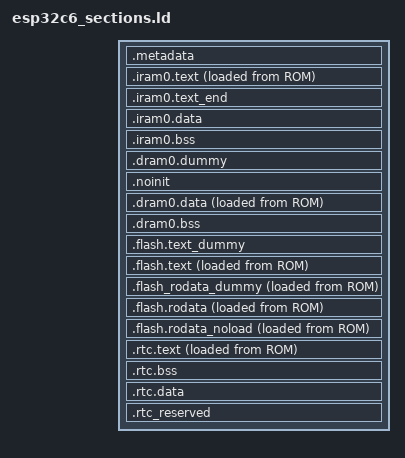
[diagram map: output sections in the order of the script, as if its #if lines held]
/****************************************************************************
 * boards/risc-v/esp32c6/common/scripts/esp32c6_sections.ld
 *
 * SPDX-License-Identifier: Apache-2.0
 *
 * Licensed to the Apache Software Foundation (ASF) under one or more
 * contributor license agreements.  See the NOTICE file distributed with
 * this work for additional information regarding copyright ownership.  The
 * ASF licenses this file to you under the Apache License, Version 2.0 (the
 * "License"); you may not use this file except in compliance with the
 * License.  You may obtain a copy of the License at
 *
 *   http://www.apache.org/licenses/LICENSE-2.0
 *
 * Unless required by applicable law or agreed to in writing, software
 * distributed under the License is distributed on an "AS IS" BASIS, WITHOUT
 * WARRANTIES OR CONDITIONS OF ANY KIND, either express or implied.  See the
 * License for the specific language governing permissions and limitations
 * under the License.
 *
 ****************************************************************************/

#include "common.ld"

/* Default entry point: */

ENTRY(__start);

SECTIONS
{
#ifdef CONFIG_ESPRESSIF_BOOTLOADER_MCUBOOT
  .metadata :
  {
    /* Magic for load header */

    LONG(0xace637d3)

    /* Application entry point address */

    KEEP(*(.entry_addr))

    /* IRAM metadata:
     * - Destination address (VMA) for IRAM region
     * - Flash offset (LMA) for start of IRAM region
     * - Size of IRAM region
     */

    LONG(ADDR(.iram0.text))
    LONG(LOADADDR(.iram0.text))
    LONG(SIZEOF(.iram0.text))

    /* DRAM metadata:
     * - Destination address (VMA) for DRAM region
     * - Flash offset (LMA) for start of DRAM region
     * - Size of DRAM region
     */

    LONG(ADDR(.dram0.data))
    LONG(LOADADDR(.dram0.data))
    LONG(SIZEOF(.dram0.data))
  } >metadata
#endif

  .iram0.text :
  {
    _iram_start = ABSOLUTE(.);

    /* Vectors go to start of IRAM */

    KEEP(*(.exception_vectors.text));
    . = ALIGN(16);

    *(.iram1)
    *(.iram1.*)

    *libsched.a:irq_dispatch.*(.text .text.* .literal .literal.*)

    *libarch.a:*(.text.esprv_intc_int_get_type .literal.esprv_intc_int_get_type)
    *libarch.a:*riscv_doirq.*(.text .text.* .literal .literal.*)
    *libarch.a:*brownout.*(.text .text.* .literal .literal.*)
    *libarch.a:*cpu.*(.text .text.* .literal .literal.*)
    *libarch.a:*gpio_hal.*(.text .text.* .literal .literal.*)
    *libarch.a:*periph_ctrl.*(.text .text.* .literal .literal.*)
    *libarch.a:*clk.*(.text .text.* .literal .literal.*)
    *libarch.a:*esp_clk.*(.text .text.* .literal .literal.*)
    *libarch.a:*esp_clk_tree.*(.text .text.* .literal .literal.*)
    *libarch.a:*esp_clk_tree_common.*(.text .text.* .literal .literal.*)
    *libarch.a:*clk_tree_hal.*(.text .text.* .literal .literal.*)
    *libarch.a:*pmu_init.*(.text .text.* .literal .literal.*)
    *libarch.a:*modem_clock.*(.text .text.* .literal .literal.*)
    *libarch.a:*regi2c_ctrl.*(.text .text.* .literal .literal.*)
    *libarch.a:*gpio_periph.*(.text .text.* .literal .literal.*)
    *libarch.a:*modem_clock_hal.*(.text .text.* .literal .literal.*)
    *libarch.a:*esp_rom_systimer.*(.text .text.* .literal .literal.*)
    *libarch.a:*esp_rom_wdt.*(.text .text.* .literal .literal.*)
    *libarch.a:*ocode_init.*(.text .text.* .literal .literal.*)
    *libarch.a:*esp_rom_regi2c_esp32c6.*(.text .text.* .literal .literal.*)
    *libarch.a:*rtc_clk.*(.text .text.* .literal .literal.*)
    *libarch.a:*rtc_clk_init.*(.text .text.* .literal .literal.*)
    *libarch.a:*pmu_sleep.*(.text .text.* .literal .literal.*)
    *libarch.a:*pmu_param.*(.text .text.* .literal .literal.*)
    *libarch.a:*rtc_time.*(.text .text.* .literal .literal.*)
    *libarch.a:*systimer.*(.text .text.* .literal .literal.*)
    *libarch.a:*systimer_hal.*(.text .text.* .literal .literal.*)
    *libarch.a:*uart_hal_iram.*(.text .text.* .literal .literal.*)
    *libarch.a:*wdt_hal_iram.*(.text .text.* .literal .literal.*)
    *libarch.a:*bootloader_banner_wrap.*(.text .text.* .literal .literal.*)
    *libarch.a:*bootloader_init.*(.text .text.* .literal .literal.*)
    *libarch.a:*bootloader_common.*(.text .text.* .literal .literal.*)
    *libarch.a:*bootloader_common_loader.*(.text .text.* .literal .literal.*)
    *libarch.a:*bootloader_console.*(.text .text.* .literal .literal.*)
    *libarch.a:*bootloader_console_loader.*(.text .text.* .literal .literal.*)
    *libarch.a:*bootloader_esp32c6.*(.text .text.* .literal .literal.*)
    *libarch.a:*bootloader_flash.*(.text .text.* .literal .literal.*)
    *libarch.a:*bootloader_flash_config_esp32c6.*(.text .text.* .literal .literal.*)
    *libarch.a:*bootloader_clock_init.*(.text .text.* .literal .literal.*)
    *libarch.a:*bootloader_clock_loader.*(.text .text.* .literal .literal.*)
    *libarch.a:*bootloader_efuse.*(.text .text.* .literal .literal.*)
    *libarch.a:*bootloader_panic.*(.text .text.* .literal .literal.*)
    *libarch.a:*bootloader_mem.*(.text .text.* .literal .literal.*)
    *libarch.a:*bootloader_random.*(.text .text.* .literal .literal.*)
    *libarch.a:*bootloader_random_esp32c6.*(.text .text.* .literal .literal.*)
    *libarch.a:*esp_image_format.*(.text .text.* .literal .literal.*)
    *libarch.a:*bootloader_soc.*(.text .text.* .literal .literal.*)
    *libarch.a:*bootloader_sha.*(.text .text.* .literal .literal.*)
    *libarch.a:*flash_encrypt.*(.text .text.* .literal .literal.*)
    *libarch.a:*cache_hal.*(.text .text.* .literal .literal.*)
    *libarch.a:*uart_hal.*(.text .text.* .literal .literal.*)
    *libarch.a:*mpu_hal.*(.text .text.* .literal .literal.*)
    *libarch.a:*mmu_hal.*(.text .text.* .literal .literal.*)
    *libarch.a:*uart_periph.*(.text .text.* .literal .literal.*)
    *libarch.a:*esp_rom_uart.*(.text .text.* .literal .literal.*)
    *libarch.a:*esp_rom_sys.*(.text .text.* .literal .literal.*)
    *libarch.a:*esp_rom_spiflash.*(.text .text.* .literal .literal.*)
    *libarch.a:*esp_efuse_fields.*(.text .text.* .literal .literal.*)
    *libarch.a:*esp_efuse_api_key.*(.text .text.* .literal .literal.*)
    *libarch.a:*esp_efuse_utility.*(.text .text.* .literal .literal.*)
    *libarch.a:*efuse_hal.*(.text .text.* .literal .literal.*)
    *libarch.a:*log.*(.text .text.* .literal .literal.*)
    *libarch.a:*log_noos.*(.text .text.* .literal .literal.*)
    *libarch.a:esp_spiflash.*(.literal .text .literal.* .text.*)

    *libc.a:sq_remlast.*(.literal .text .literal.* .text.*)

    esp_head.*(.literal .text .literal.* .text.*)
    esp_start.*(.literal .text .literal.* .text.*)

    *(.wifi0iram .wifi0iram.*)
    *(.wifirxiram .wifirxiram.*)
    *(.wifislpiram .wifislpiram.*)
    *(.wifiorslpiram .wifiorslpiram.*)
    *(.wifislprxiram .wifislprxiram.*)
    *(.wifiextrairam .wifiextrairam.*)

  } >iram0_0_seg AT > ROM

  /* Marks the end of IRAM code segment */

  .iram0.text_end (NOLOAD) :
  {
    . = ALIGN (16);
  } >iram0_0_seg

  .iram0.data :
  {
    . = ALIGN(16);
    *(.iram.data)
    *(.iram.data*)
  } >iram0_0_seg

  .iram0.bss (NOLOAD) :
  {
    . = ALIGN(16);
    *(.iram.bss)
    *(.iram.bss*)

    . = ALIGN(16);
    _iram_end = ABSOLUTE(.);
  } >iram0_0_seg

  /* This section is required to skip .iram0.text area because iram0_0_seg
   * and dram0_0_seg reflect the same address space on different buses.
   */

  .dram0.dummy (NOLOAD):
  {
    . = ORIGIN(dram0_0_seg) + _iram_end - _iram_start;
  } >dram0_0_seg

  .noinit (NOLOAD):
  {
    /* This section contains data that is not initialized during load,
     * or during the application's initialization sequence.
     */
    . = ALIGN(8);
    *(.noinit)
    *(.noinit.*)
  } >dram0_0_seg

  .dram0.data :
  {
    . = ALIGN (16);
    _data_start = ABSOLUTE(.);
    _sdata = ABSOLUTE(.);
    *(.data)
    *(.data.*)
    *(.gnu.linkonce.d.*)
    *(.data1)
    __global_pointer$ = . + 0x800;
    *(.sdata)
    *(.sdata.*)
    *(.gnu.linkonce.s.*)
    *(.sdata2)
    *(.sdata2.*)
    *(.gnu.linkonce.s2.*)
    *(.jcr)
    *(.dram1)
    *(.dram1.*)

    *libsched.a:irq_dispatch.*(.rodata .rodata.*)

    *libarch.a:*(.rodata.esprv_intc_int_get_type)
    *libarch.a:*riscv_doirq.*(.rodata .rodata.*)
    *libarch.a:*brownout.*(.rodata .rodata.*)
    *libarch.a:*cpu.*(.rodata .rodata.*)
    *libarch.a:*gpio_hal.*(.rodata .rodata.*)
    *libarch.a:*periph_ctrl.*(.rodata .rodata.*)
    *libarch.a:*clk.*(.rodata .rodata.*)
    *libarch.a:*esp_clk.*(.rodata .rodata.*)
    *libarch.a:*esp_clk_tree.*(.rodata .rodata.*)
    *libarch.a:*esp_clk_tree_common.*(.rodata .rodata.*)
    *libarch.a:*clk_tree_hal.*(.rodata .rodata.*)
    *libarch.a:*pmu_init.*(.rodata .rodata.*)
    *libarch.a:*modem_clock.*(.rodata .rodata.*)
    *libarch.a:*modem_clock_hal.*(.rodata .rodata.*)
    *libarch.a:*regi2c_ctrl.*(.rodata .rodata.*)
    *libarch.a:*gpio_periph.*(.rodata .rodata.*)
    *libarch.a:*esp_rom_systimer.*(.rodata .rodata.*)
    *libarch.a:*esp_rom_wdt.*(.rodata .rodata.*)
    *libarch.a:*ocode_init.*(.rodata .rodata.*)
    *libarch.a:*esp_rom_regi2c_esp32c6.*(.rodata .rodata.*)
    *libarch.a:*rtc_clk.*(.rodata .rodata.*)
    *libarch.a:*rtc_clk_init.*(.rodata .rodata.*)
    *libarch.a:*pmu_param.*(.rodata .rodata.*)
    *libarch.a:*pmu_sleep.*(.rodata .rodata.*)
    *libarch.a:*rtc_time.*(.rodata .rodata.*)
    *libarch.a:*systimer.*(.rodata .rodata.*)
    *libarch.a:*systimer_hal.*(.rodata .rodata.*)
    *libarch.a:*uart_hal_iram.*(.rodata .rodata.*)
    *libarch.a:*wdt_hal_iram.*(.rodata .rodata.*)
    *libarch.a:*bootloader_banner_wrap.*(.rodata .rodata.*)
    *libarch.a:*bootloader_init.*(.rodata .rodata.*)
    *libarch.a:*bootloader_common.*(.rodata .rodata.*)
    *libarch.a:*bootloader_common_loader.*(.rodata .rodata.*)
    *libarch.a:*bootloader_console.*(.rodata .rodata.*)
    *libarch.a:*bootloader_console_loader.*(.rodata .rodata.*)
    *libarch.a:*bootloader_esp32c6.*(.rodata .rodata.*)
    *libarch.a:*bootloader_flash.*(.rodata .rodata.*)
    *libarch.a:*bootloader_flash_config_esp32c6.*(.rodata .rodata.*)
    *libarch.a:*bootloader_clock_init.*(.rodata .rodata.*)
    *libarch.a:*bootloader_clock_loader.*(.rodata .rodata.*)
    *libarch.a:*bootloader_efuse.*(.rodata .rodata.*)
    *libarch.a:*bootloader_panic.*(.rodata .rodata.*)
    *libarch.a:*bootloader_mem.*(.rodata .rodata.*)
    *libarch.a:*bootloader_random.*(.rodata .rodata.*)
    *libarch.a:*bootloader_random_esp32c6.*(.rodata .rodata.*)
    *libarch.a:*esp_image_format.*(.rodata .rodata.*)
    *libarch.a:*bootloader_soc.*(.rodata .rodata.*)
    *libarch.a:*bootloader_sha.*(.rodata .rodata.*)
    *libarch.a:*flash_encrypt.*(.rodata .rodata.*)
    *libarch.a:*cache_hal.*(.rodata .rodata.*)
    *libarch.a:*uart_hal.*(.rodata .rodata.*)
    *libarch.a:*mpu_hal.*(.rodata .rodata.*)
    *libarch.a:*mmu_hal.*(.rodata .rodata.*)
    *libarch.a:*uart_periph.*(.rodata .rodata.*)
    *libarch.a:*esp_rom_uart.*(.rodata .rodata.*)
    *libarch.a:*esp_rom_sys.*(.rodata .rodata.*)
    *libarch.a:*esp_rom_spiflash.*(.rodata .rodata.*)
    *libarch.a:*esp_efuse_fields.*(.rodata .rodata.*)
    *libarch.a:*esp_efuse_api_key.*(.rodata .rodata.*)
    *libarch.a:*esp_efuse_utility.*(.rodata .rodata.*)
    *libarch.a:*efuse_hal.*(.rodata .rodata.*)
    *libarch.a:*log.*(.rodata .rodata.*)
    *libarch.a:*log_noos.*(.rodata .rodata.*)
    *libarch.a:esp_spiflash.*(.rodata .rodata.*)

    esp_head.*(.rodata .rodata.*)
    esp_start.*(.rodata .rodata.*)

    . = ALIGN(4);
    _edata = ABSOLUTE(.);
    _data_end = ABSOLUTE(.);
  } >dram0_0_seg AT > ROM

  /* Shared RAM */

  .dram0.bss (NOLOAD) :
  {
    . = ALIGN (8);
    _bss_start = ABSOLUTE(.);
    _sbss = ABSOLUTE(.);
    *(.dynsbss)
    *(.sbss)
    *(.sbss.*)
    *(.gnu.linkonce.sb.*)
    *(.scommon)
    *(.sbss2)
    *(.sbss2.*)
    *(.gnu.linkonce.sb2.*)
    *(.dynbss)
    *(.bss)
    *(.bss.*)
    *(.share.mem)
    *(.gnu.linkonce.b.*)
    *(COMMON)

    . = ALIGN (32);
    _ebss = ABSOLUTE(.);
    _bss_end = ABSOLUTE(.);
  } >dram0_0_seg

  _image_irom_vma = ADDR(.flash.text);
  _image_irom_lma = LOADADDR(.flash.text);
  _image_irom_size = SIZEOF(.flash.text);

  .flash.text_dummy (NOLOAD) :
    {
    . = ALIGN(0x10000);
    } > ROM

  .flash.text : ALIGN(0xFFFF)
  {
    _stext = .;
    _instruction_reserved_start = ABSOLUTE(.);  /* This is a symbol marking the flash.text start, this can be used for mmu driver to maintain virtual address */
    _text_start = ABSOLUTE(.);

    *(EXCLUDE_FILE(*libnet80211.a *libpp.a) .wifi0iram EXCLUDE_FILE(*libnet80211.a *libpp.a) .wifi0iram.*)
    *(EXCLUDE_FILE(*libpp.a) .wifiorslpiram EXCLUDE_FILE(*libpp.a) .wifiorslpiram.*)
    *(EXCLUDE_FILE(*libnet80211.a *libpp.a) .wifirxiram EXCLUDE_FILE(*libnet80211.a *libpp.a) .wifirxiram.*)
    *(EXCLUDE_FILE(*libnet80211.a *libpp.a) .wifislprxiram EXCLUDE_FILE(*libnet80211.a *libpp.a) .wifislprxiram.*)

    *(.literal .text .literal.* .text.* .stub .gnu.warning .gnu.linkonce.literal.* .gnu.linkonce.t.*.literal .gnu.linkonce.t.*)
    *(.irom0.text) /* catch stray ICACHE_RODATA_ATTR */
    *(.fini.literal)
    *(.fini)
    *(.gnu.version)

    . += 16;

    _text_end = ABSOLUTE(.);
    _instruction_reserved_end = ABSOLUTE(.);  /* This is a symbol marking the flash.text end, this can be used for mmu driver to maintain virtual address */
    _etext = .;

    /* Similar to _iram_start, this symbol goes here so it is
     * resolved by addr2line in preference to the first symbol in
     * the flash.text segment.
     */

    _flash_cache_start = ABSOLUTE(0);
  } >default_code_seg AT > ROM

  _image_drom_vma = ADDR(.flash.rodata);
  _image_drom_lma = LOADADDR(.flash.rodata);
  _image_drom_size = SIZEOF(.flash.rodata);

  .flash_rodata_dummy (NOLOAD) :
  {
    . += SIZEOF(.flash.text);
    . = ALIGN(0x10000);
    _rodata_reserved_start = ABSOLUTE(.);  /* This is a symbol marking the flash.rodata start, this can be used for mmu driver to maintain virtual address */
    _rodata_start = ABSOLUTE(.);
  } >default_rodata_seg AT > ROM

  .flash.rodata : ALIGN(0xFFFF)
  {
    _srodata = ABSOLUTE(.);

    *(.rodata)
    *(.rodata.*)
    *(.rodata_wlog_verbose.*)
    *(.rodata_wlog_debug.*)
    *(.rodata_wlog_info.*)
    *(.rodata_wlog_warning.*)
    *(.rodata_wlog_error.*)

    *(.srodata.*)

    *(.irom1.text) /* catch stray ICACHE_RODATA_ATTR */
    *(.gnu.linkonce.r.*)
    *(.rodata1)
    __XT_EXCEPTION_TABLE_ = ABSOLUTE(.);
    *(.xt_except_table)
    *(.gcc_except_table .gcc_except_table.*)
    *(.gnu.linkonce.e.*)
    *(.gnu.version_r)
    . = (. + 3) & ~ 3;
    __eh_frame = ABSOLUTE(.);
    KEEP(*(.eh_frame))
    . = (. + 7) & ~ 3;

    /* C++ constructor and destructor tables:
     * RISC-V GCC is configured with --enable-initfini-array so it emits an
     * .init_array section instead.
     */

    _sinit = ABSOLUTE(.);
    KEEP (*(EXCLUDE_FILE (*crtend.* *crtbegin.*) .init_array.*))
    KEEP (*(EXCLUDE_FILE (*crtend.* *crtbegin.*) .init_array))
    _einit = ABSOLUTE(.);
    KEEP (*crtbegin.o(.dtors))
    KEEP (*(EXCLUDE_FILE (*crtend.o) .dtors))
    KEEP (*(SORT(.dtors.*)))
    KEEP (*(.dtors))

    /* C++ exception handlers table: */

    __XT_EXCEPTION_DESCS_ = ABSOLUTE(.);
    *(.xt_except_desc)
    *(.gnu.linkonce.h.*)
    __XT_EXCEPTION_DESCS_END__ = ABSOLUTE(.);
    *(.xt_except_desc_end)
    *(.dynamic)
    *(.gnu.version_d)
    _erodata = ABSOLUTE(.);

    /* Literals are also RO data. */

    _lit4_start = ABSOLUTE(.);
    *(*.lit4)
    *(.lit4.*)
    *(.gnu.linkonce.lit4.*)
    _lit4_end = ABSOLUTE(.);
    . = ALIGN(4);
  } >default_rodata_seg AT > ROM

  .flash.rodata_noload (NOLOAD) :
  {
    /*
      This is a symbol marking the flash.rodata end, this can be used for mmu driver to maintain virtual address
      We don't need to include the noload rodata in this section
    */
    _rodata_end = ABSOLUTE(.);
    _rodata_reserved_end = ABSOLUTE(.);
    . = ALIGN (4);
  } > default_rodata_seg AT > ROM

  /* RTC fast memory holds RTC wake stub code !*/

  .rtc.text :
  {
    . = ALIGN(4);
    *(.rtc.literal .rtc.text)
    *(.rtc.entry.text)
    /* 16B padding for possible CPU prefetch and 4B alignment for PMS split lines */
    . += 16;
    . = ALIGN(4);

  } > lp_ram_seg AT > ROM

  /* RTC BSS section. */

  .rtc.bss (NOLOAD) :
  {
    *(.rtc.bss)
  } > lp_ram_seg

  .rtc.data :
  {
    _rtc_data_start = ABSOLUTE(.);
    *(.rtc.data)
    *(.rtc.data.*)
    *(.rtc.rodata)
    *(.rtc.rodata.*)
    _rtc_data_end = ABSOLUTE(.);
  } > lp_ram_seg

  /* This section holds RTC data that should have fixed addresses.
   * The data are not initialized at power-up and are retained during deep sleep.
   */
  .rtc_reserved (NOLOAD):
  {
    . = ALIGN(4);
    _rtc_reserved_start = ABSOLUTE(.);
    /* New data can only be added here to ensure existing data are not moved.
       Because data have adhered to the end of the segment and code is relied on it.
       >> put new data here << */

    *(.rtc_timer_data_in_rtc_mem .rtc_timer_data_in_rtc_mem.*)
    KEEP(*(.bootloader_data_rtc_mem .bootloader_data_rtc_mem.*))
    _rtc_reserved_end = ABSOLUTE(.);
  } > rtc_reserved_seg

  _rtc_reserved_length = _rtc_reserved_end - _rtc_reserved_start;
  ASSERT((_rtc_reserved_length <= LENGTH(rtc_reserved_seg)),
          "RTC reserved segment data does not fit.")

}
